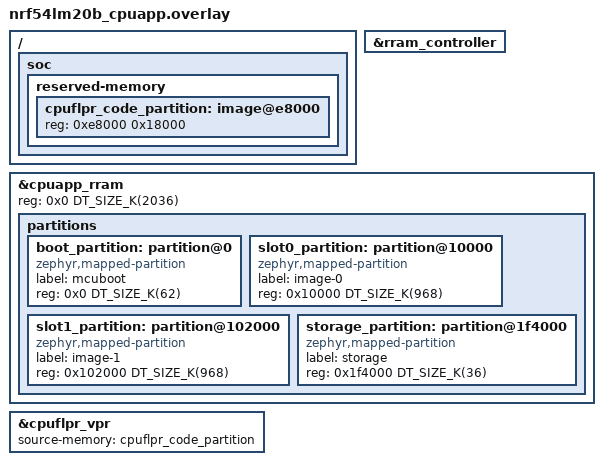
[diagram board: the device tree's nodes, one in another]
/*
 * Coupled FLPR OTA (Strategy B) for nRF54LM20B cpuapp.
 *
 * - FLPR storage copy inside MCUboot slot0 @ 0xE8000 (96 KiB)
 * - Full 968 KiB slots (no WITH_FLPR_PARTITIONS carve-out)
 * - Removes outside-slot cpuflpr_rram @ 0x1E5000 from nordic-flpr
 * - Restores full cpuapp_rram (2036 KiB) so slot1+storage are in-bounds
 */

&rram_controller {
	/delete-node/ rram@1e5000;
};

/* nordic-flpr shrinks RRAM to 1940 KiB for outside-slot FLPR; undo that. */
&cpuapp_rram {
	reg = <0x0 DT_SIZE_K(2036)>;
	ranges = <0x0 0x0 DT_SIZE_K(2036)>;
};

/ {
	soc {
		reserved-memory {
			#address-cells = <1>;
			#size-cells = <1>;

			cpuflpr_code_partition: image@e8000 {
				/* FLPR payload — updated with slot0 via MCUboot swap */
				reg = <0xe8000 0x18000>;
			};
		};
	};
};

&cpuapp_rram {
	/delete-node/ partitions;

	partitions {
		ranges;
		#address-cells = <1>;
		#size-cells = <1>;

		boot_partition: partition@0 {
			compatible = "zephyr,mapped-partition";
			label = "mcuboot";
			reg = <0x0 DT_SIZE_K(62)>;
		};

		slot0_partition: partition@10000 {
			compatible = "zephyr,mapped-partition";
			label = "image-0";
			reg = <0x10000 DT_SIZE_K(968)>;
		};

		slot1_partition: partition@102000 {
			compatible = "zephyr,mapped-partition";
			label = "image-1";
			reg = <0x102000 DT_SIZE_K(968)>;
		};

		storage_partition: partition@1f4000 {
			compatible = "zephyr,mapped-partition";
			label = "storage";
			reg = <0x1f4000 DT_SIZE_K(36)>;
		};
	};
};

&cpuflpr_vpr {
	source-memory = <&cpuflpr_code_partition>;
};
